# ET6801 register map
Vendor: ETMCU Inc.; File version: v0.0.1
CPU: CM7 r2p1, little endian, MPU, FPU, I-cache, D-cache, ITCM, DTCM, 4 interrupt priority bits
Registers are 32-bit, read-write, reset 0x0 unless marked. A register's access mark holds for its fields unless they carry their own. Offsets are from the block's base; [hi:lo] are bit positions.

## CAN0 (part 1 of 2) — Provide an overview of the purpose and functionality of the peripheral: mttcan_cfg
Base 0x40518000
Same registers: CAN1 0x40520000, CAN2 0x40528000
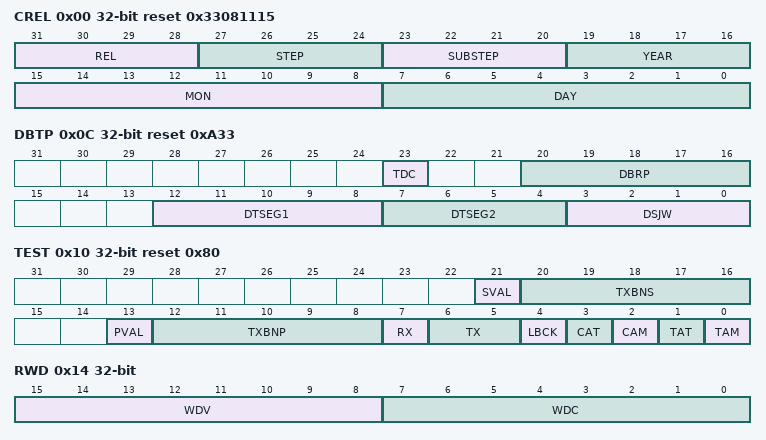
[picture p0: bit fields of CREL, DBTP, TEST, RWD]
0x00 CREL ro reset 0x33081115
  [31:28] REL — Core Release One digit, BCD-coded.
  [27:24] STEP — Step of Core Release One digit, BCD-coded.
  [23:20] SUBSTEP — Sub-step of Core Release One digit, BCD-coded.
  [19:16] YEAR — Time Stamp Year One digit, BCD-coded. This ﬁeld is set by generic parameter on M_TTCAN synthesis.
  [15:8] MON — Time Stamp Month Two digits, BCD-coded. This ﬁeld is set by generic parameter on M_TTCAN synthesis.
  [7:0] DAY — Time Stamp Day Two digits, BCD-coded. This ﬁeld is set by generic parameter on M_TTCAN synthesis.
0x04 ENDN ro reset 0x87654321
  [31:0] ETV — Endianness Test Value The endianness test value is 0x87654321.
0x0C DBTP reset 0xA33
  [23] TDC — Transmitter Delay Compensation 0= Transmitter Delay Compensation disabled 1= Transmitter Delay Compensation enabled
  [20:16] DBRP ro — Data Bit Rate Prescaler 0x00-0x1F The value by which the oscillator frequency is divided for generating the bit time quanta. The bit time is built up from a multiple of this quanta. Valid values for the Bit Rate Prescaler are 0 to 31. When TDC = '1', the range is limited to 0,1. The actual interpretation by the hardware of this value is such that one more than the value programmed here is used.
  [12:8] DTSEG1 ro — Data time segment before sample point 0x00-0x1F Valid values are 0 to 31. The actual interpretation by the hardware of this value is such that one more than the programmed value is used.
  [7:4] DTSEG2 ro — Data time segment after sample point 0x0-0xF Valid values are 0 to 15. The actual interpretation by the hardware of this value is such that one more than the programmed value is used.
  [3:0] DSJW ro — Data (Re)Synchronization Jump Width 0x0-0xF Valid values are 0 to 15. The actual interpretation by the hardware of this value is such that one more than the value programmed here is used.
0x10 TEST ro reset 0x80
  [21] SVAL — Started Valid 0= Value of TXBNS not valid 1= Value of TXBNS valid
  [20:16] TXBNS — Tx Buffer Number Started 0x00-0x1F Tx Buffer number of message whose transmission was started last. Valid when SVAL is set. Valid values are 0 to 31.
  [13] PVAL — Prepared Valid 0= Value of TXBNP not valid 1= Value of TXBNP valid
  [12:8] TXBNP — Tx Buffer Number Prepared 0x00-0x1F Tx Buffer number of message that is ready for transmission. Valid when PVAL is set. Valid values are 0 to 31.
  [7] RX — Receive Pin Monitors the actual value of pin m_ttcan_rx 0= The CAN bus is dominant (m_ttcan_rx = '0') 1= The CAN bus is recessive (m_ttcan_rx = '1')
  [6:5] TX — Control of Transmit Pin 00 Reset value, m_ttcan_tx controlled by the CAN Core, updated at the end of the CAN bit time 01 Sample Point can be monitored at pin m_ttcan_tx 10 Dominant ('0') level at pin m_ttcan_tx 11 Recessive ('1') at pin m_ttcan_tx
  [4] LBCK — Loop Back Mode 0= Reset value, Loop Back Mode is disabled 1= Loop Back Mode is enabled (see Section 3.1.9, Test Modes)
  [3] CAT — Check ASC Transmit Control Monitors level at output pin m_ttcan_asct. 0= Output pin m_ttcan_asct = '0' 1= Output pin m_ttcan_asct = '1'
  [2] CAM — Check ASC Multiplexer Control Monitors level at output pin m_ttcan_ascm. 0= Output pin m_ttcan_ascm = '0' 1= Output pin m_ttcan_ascm = '1'
  [1] TAT — Test ASC Transmit Control Controls output pin m_ttcan_asct in test mode, ORed with the signal from the FSE 0= Level at pin m_ttcan_asct controlled by FSE 1= Level at pin m_ttcan_asct = '1'
  [0] TAM — Test ASC Multiplexer Control Controls output pin m_ttcan_ascm in test mode, ORed with the signal from the FSE 0= Level at pin m_ttcan_ascm controlled by FSE 1= Level at pin m_ttcan_ascm = '1'
0x14 RWD ro
  [15:8] WDV — Watchdog Value Actual Message RAM Watchdog Counter Value.
  [7:0] WDC — Watchdog Conﬁguration Start value of the Message RAM Watchdog Counter. With the reset value of "00" the counter is disabled.
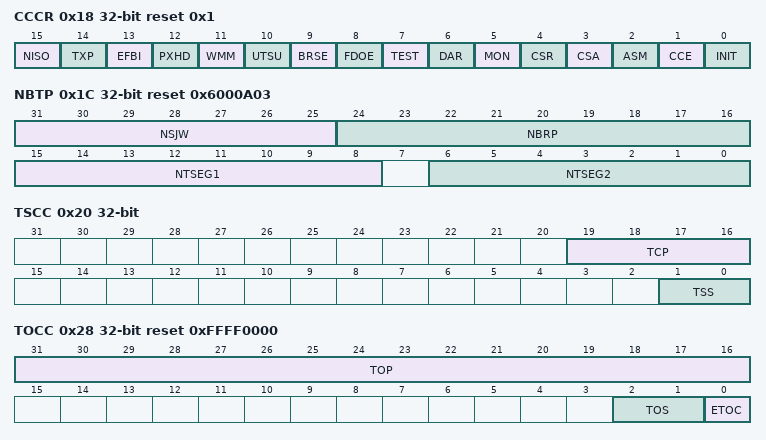
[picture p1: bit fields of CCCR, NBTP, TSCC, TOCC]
0x18 CCCR reset 0x1
  [15] NISO — Non ISO Operation If this bit is set, the M_TTCAN uses the CAN FD frame format as speciﬁed by the Bosch CAN FD Speciﬁcation V1.0. 0= CAN FD frame format according to ISO 11898-1:2015 1= CAN FD frame format according to Bosch CAN FD Speciﬁcation V1.0
  [14] TXP — Transmit Pause If this bit is set, the M_TTCAN pauses for two CAN bit times before starting the next transmission after itself has successfully transmitted a frame (see Section 3.5). 0= Transmit pause disabled 1= Transmit pause enabled
  [13] EFBI — Edge Filtering during Bus Integration 0= Edge ﬁltering disabled 1= Two consecutive dominant tq required to detect an edge for hard synchronization
  [12] PXHD — Protocol Exception Handling Disable 0= Protocol exception handling enabled 1= Protocol exception handling disabled
  [11] WMM — Wide Message Marker Enables the use of 16-bit Wide Message Markers. When 16-bit Wide Message Markers are used (WMM = '1'), 16-bit internal timestamping is disabled for the Tx Event FIFO. 0= 8-bit Message Marker used 1= 16-bit Message Marker used, replacing 16-bit timestamps in Tx Event FIFO
  [10] UTSU — Use Timestamping Unit When UTSU is set, 16-bit Wide Message Markers are also enabled regardless of the value of WMM. 0= Internal time stamping 1= External time stamping by TSU
  [9] BRSE — Bit Rate Switch Enable 0= Bit rate switching for transmissions disabled 1= Bit rate switching for transmissions enabled
  [8] FDOE — FD Operation Enable 0= FD operation disabled 1= FD operation enabled
  [7] TEST — Test Mode Enable 0= Normal operation, register TEST holds reset values 1= Test Mode, write access to register TEST enabled
  [6] DAR — Disable Automatic Retransmission 0= Automatic retransmission of messages not transmitted successfully enabled 1= Automatic retransmission disabled
  [5] MON — Bus Monitoring Mode Bit MON can only be set by the Host when both CCE and INIT are set to '1'. The bit can be reset by the Host at any time. 0= Bus Monitoring Mode is disabled 1= Bus Monitoring Mode is enabled
  [4] CSR — Clock Stop Request 0= No clock stop is requested 1= Clock stop requested. When clock stop is requested, ﬁrst INIT and then CSA will be set after all pending transfer requests have been completed and the CAN bus reached idle.
  [3] CSA — Clock Stop Acknowledge 0= No clock stop acknowledged 1= M_TTCAN may be set in power down by stopping m_ttcan_hclk and m_ttcan_cclk
  [2] ASM — Restricted Operation Mode Bit ASM can only be set by the Host when both CCE and INIT are set to '1'. The bit can be reset by the Host at any time. For a description of the Restricted Operation Mode see Section 3.1.5. 0= Normal CAN operation 1= Restricted Operation Mode active
  [1] CCE — Conﬁguration Change Enable 0= The CPU has no write access to the protected conﬁguration registers 1= The CPU has write access to the protected conﬁguration registers (while CCCR.INIT = '1')
  [0] INIT — Initialization 0= Normal Operation 1= Initialization is started
0x1C NBTP ro reset 0x6000A03
  [31:25] NSJW — Nominal (Re)Synchronization Jump Width 0x00-0x7F Valid values are 0 to 127. The actual interpretation by the hardware of this value is such that one more than the value programmed here is used.
  [24:16] NBRP — Nominal Bit Rate Prescaler 0x000-0x1FFThe value by which the oscillator frequency is divided for generating the bit time quanta. The bit time is built up from a multiple of this quanta. Valid values for the Bit Rate Prescaler are 0 to 511. The actual interpretation by the hardware of this value is such that one more than the value programmed here is used.
  [15:8] NTSEG1 — Nominal Time segment before sample point 0x01-0xFF Valid values are 1 to 255. The actual interpretation by the hardware of this value is such that one more than the programmed value is used.
  [6:0] NTSEG2 — Nominal Time segment after sample point 0x01-0x7F Valid values are 1 to 127. The actual interpretation by the hardware of this value is such that one more than the programmed value is used.
0x20 TSCC ro
  [19:16] TCP — Timestamp Counter Prescaler 0x0-0xF Conﬁgures the timestamp and timeout counters time unit in multiples of CAN bit times [1...16]. The actual interpretation by the hardware of this value is such that one more than the value programmed here is used.
  [1:0] TSS — Timestamp Select 00= Timestamp counter value always 0x0000 01= Timestamp counter value incremented according to TCP 10= External timestamp counter value used 11= Same as "00"
0x24 TSCV ro
  [15:0] TSC — Timestamp Counter The internal/external Timestamp Counter value is captured on start of frame (both Rx and Tx). When TSCC.TSS = "01", the Timestamp Counter is incremented in multiples of CAN bit times [1...16] depending on the conﬁguration of TSCC.TCP. A wrap around sets interrupt ﬂag IR.TSW. Write access resets the counter to zero. When TSCC.TSS = "10", TSC reﬂects the external Timestamp Counter value. A write access has no impact.
0x28 TOCC ro reset 0xFFFF0000
  [31:16] TOP — Timeout Period Start value of the Timeout Counter (down-counter). Conﬁgures the Timeout Period.
  [2:1] TOS — Timeout Select When operating in Continuous mode, a write to TOCV presets the counter to the value conﬁgured by TOCC.TOP and continues down-counting. When the Timeout Counter is controlled by one of the FIFOs, an empty FIFO presets the counter to the value conﬁgured by TOCC.TOP. Down-counting is started when the ﬁrst FIFO element is stored. 00= Continuous operation 01= Timeout controlled by Tx Event FIFO 10= Timeout controlled by Rx FIFO 0 11= Timeout controlled by Rx FIFO 1
  [0] ETOC — Enable Timeout Counter 0= Timeout Counter disabled 1= Timeout Counter enabled
0x2C TOCV ro reset 0xFFFF
  [15:0] TOC — Timeout Counter The Timeout Counter is decremented in multiples of CAN bit times [1...16] depending on the conﬁguration of TSCC.TCP. When decremented to zero, interrupt ﬂag IR.TOO is set and the Timeout Counter is stopped. Start and reset/restart conditions are conﬁgured via TOCC.TOS.
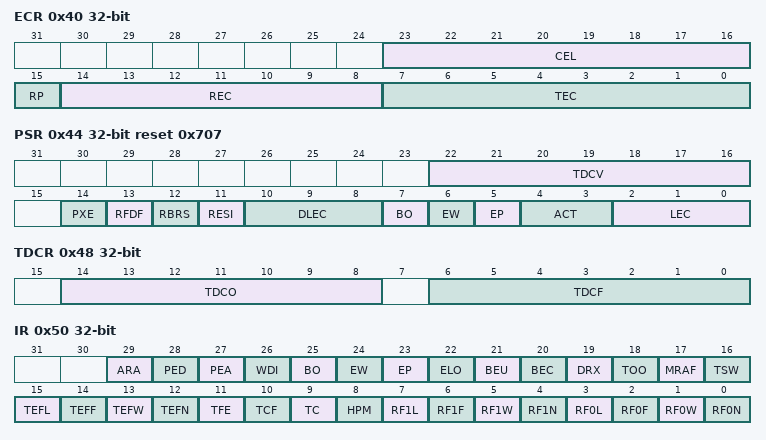
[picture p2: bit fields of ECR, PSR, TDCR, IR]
0x40 ECR ro
  [23:16] CEL — CAN Error Logging The counter is incremented each time when a CAN protocol error causes the 8-bit Transmit Error Counter TEC or the 7-bit Receive Error Counter REC to be incremented. The counter is also incremented when the Bus_Off limit is reached. It is not incremented when only RP is set without changing REC. The increment of CEL follows after the increment of REC or TEC. The counter is reset by read access to CEL. The counter stops at 0xFF; the next increment of TEC or REC sets interrupt ﬂag IR.ELO.
  [15] RP — Receive Error Passive 0= The Receive Error Counter is below the error passive level of 128 1= The Receive Error Counter has reached the error passive level of 128
  [14:8] REC — Receive Error Counter Actual state of the Receive Error Counter, values between 0 and 127
  [7:0] TEC — Transmit Error Counter Actual state of the Transmit Error Counter, values between 0 and 255
0x44 PSR ro reset 0x707
  [22:16] TDCV — Transmitter Delay Compensation Value 0x00-0x7F Position of the secondary sample point, deﬁned by the sum of the measured delay from m_ttcan_tx to m_ttcan_rx and TDCR.TDCO. The SSP position is, in the data phase, the number of mtq between the start of the transmitted bit and the secondary sample point Valid values are 0 to 127 mtq.
  [14] PXE — Protocol Exception Event 0= No protocol exception event occurred since last read access 1= Protocol exception event occurred
  [13] RFDF — Received a CAN FD Message This bit is set independent of acceptance ﬁltering. 0= Since this bit was reset by the CPU, no CAN FD message has been received 1= Message in CAN FD format with FDF ﬂag set has been received
  [12] RBRS — BRS ﬂag of last received CAN FD Message This bit is set together with RFDF, independent of acceptance ﬁltering. 0= Last received CAN FD message did not have its BRS ﬂag set 1= Last received CAN FD message had its BRS ﬂag set
  [11] RESI — ESI ﬂag of last received CAN FD Message This bit is set together with RFDF, independent of acceptance ﬁltering. 0= Last received CAN FD message did not have its ESI ﬂag set 1= Last received CAN FD message had its ESI ﬂag set
  [10:8] DLEC — Data Phase Last Error Code Type of last error that occurred in the data phase of a CAN FD format frame with its BRS ﬂag set. Coding is the same as for LEC. This ﬁeld will be cleared to zero when a CAN FD format frame with its BRS ﬂag set has been transferred (reception or transmission) without error.
  [7] BO — Bus_Off Status 0= The M_TTCAN is not Bus_Off 1= The M_TTCAN is in Bus_Off state
  [6] EW — Warning Status 0= Both error counters are below the Error_Warning limit of 96 1= At least one of error counter has reached the Error_Warning limit of 96
  [5] EP — Error Passive 0= The M_TTCAN is in the Error_Active state. It normally takes part in bus communication and sends an active error ﬂag when an error has been detected 1= The M_TTCAN is in the Error_Passive state
  [4:3] ACT — Activity Monitors the module's CAN communication state. 00= Synchronizing - node is synchronizing on CAN communication 01= Idle - node is neither receiver nor transmitter 10= Receiver - node is operating as receiver 11= Transmitter - node is operating as transmitter
  [2:0] LEC — Last Error Code The LEC indicates the type of the last error to occur on the CAN bus. This ﬁeld will be cleared to '0' when a message has been transferred (reception or transmission) without error.
0x48 TDCR ro
  [14:8] TDCO — Transmitter Delay Compensation SSP Offset 0x00-0x7F Offset value deﬁning the distance between the measured delay from m_ttcan_tx to m_ttcan_rx and the secondary sample point. Valid values are 0 to 127 mtq.
  [6:0] TDCF — Transmitter Delay Compensation Filter Window Length 0x00-0x7F Deﬁnes the minimum value for the SSP position, dominant edges on m_ttcan_rx that would result in an earlier SSP position are ignored for transmitter delay measurement. The feature is enabled when TDCF is conﬁgured to a value greater than TDCO. Valid values are 0 to 127 mtq.
0x50 IR
  [29] ARA — Access to Reserved Address 0= No access to reserved address occurred 1= Access to reserved address occurred
  [28] PED — Protocol Error in Data Phase (Data Bit Time is used) 0= No protocol error in data phase 1= Protocol error in data phase detected (PSR.DLEC ≠ 0,7)
  [27] PEA — Protocol Error in Arbitration Phase (Nominal Bit Time is used) 0= No protocol error in arbitration phase 1= Protocol error in arbitration phase detected (PSR.LEC ≠ 0,7)
  [26] WDI — Watchdog Interrupt 0= No Message RAM Watchdog event occurred 1= Message RAM Watchdog event due to missing READY
  [25] BO — Bus_Off Status 0= Bus_Off status unchanged 1= Bus_Off status changed
  [24] EW — Warning Status 0= Error_Warning status unchanged 1= Error_Warning status changed
  [23] EP — Error Passive 0= Error_Passive status unchanged 1= Error_Passive status changed
  [22] ELO — Error Logging Overﬂow 0= CAN Error Logging Counter did not overﬂow 1= Overﬂow of CAN Error Logging Counter occurred
  [21] BEU — Bit Error Uncorrected Message RAM bit error detected, uncorrected. Controlled by input signal m_ttcan_aeim_berr[1] generated by an optional external parity / ECC logic attached to the Message RAM. An uncorrected Message RAM bit error sets CCCR.INIT to '1'. This is done to avoid transmission of corrupted data. 0= No bit error detected when reading from Message RAM 1= Bit error detected, uncorrected (e.g. parity logic)
  [20] BEC — Bit Error Corrected Message RAM bit error detected and corrected. Controlled by input signal m_ttcan_aeim_berr[0] generated by an optional external parity / ECC logic attached to the Message RAM. 0= No bit error detected when reading from Message RAM 1= Bit error detected and corrected (e.g. ECC)
  [19] DRX — Message stored to Dedicated Rx Buffer The ﬂag is set whenever a received message has been stored into a dedicated Rx Buffer. 0= No Rx Buffer updated 1= At least one received message stored into a Rx Buffer
  [18] TOO — Timeout Occurred 0= No timeout 1= Timeout reached
  [17] MRAF — Message RAM Access Failure The ﬂag is set, when the Rx Handler • has not completed acceptance ﬁltering or storage of an accepted message until the arbitration ﬁeld of the following message has been received. In this case acceptance ﬁltering or message storage is aborted and the Rx Handler starts processing of the following message. • was not able to write a message to the Message RAM. In this case message storage is aborted. In both cases the FIFO put index is not updated resp. the New Data ﬂag for a dedicated Rx Buffer is not set, a partly stored message is overwritten when the next message is stored to this location. The ﬂag is also set when the Tx Handler was not able to read a message from the Message RAM in time. In this case message transmission is aborted. In case of a Tx Handler access failure the M_TTCAN is switched into Restricted Operation Mode (see Section 3.1.5). To leave Restricted Operation Mode, the Host CPU has to reset CCCR.ASM. 0= No Message RAM access failure occurred 1= Message RAM access failure occurred
  [16] TSW — Timestamp Wraparound 0= No timestamp counter wrap-around 1= Timestamp counter wrapped around
  [15] TEFL — Tx Event FIFO Element Lost 0= No Tx Event FIFO element lost 1= Tx Event FIFO element lost, also set after write attempt to Tx Event FIFO of size zero
  [14] TEFF — Tx Event FIFO Full 0= Tx Event FIFO not full 1= Tx Event FIFO full
  [13] TEFW — Tx Event FIFO Watermark Reached 0= Tx Event FIFO ﬁll level below watermark 1= Tx Event FIFO ﬁll level reached watermark
  [12] TEFN — Tx Event FIFO New Entry 0= Tx Event FIFO unchanged 1= Tx Handler wrote Tx Event FIFO element
  [11] TFE — Tx FIFO Empty 0= Tx FIFO non-empty 1= Tx FIFO empty
  [10] TCF — Transmission Cancellation Finished 0= No transmission cancellation ﬁnished 1= Transmission cancellation ﬁnished
  [9] TC — Transmission Completed 0= No transmission completed 1= Transmission completed
  [8] HPM — High Priority Message 0= No high priority message received 1= High priority message received
  [7] RF1L — Rx FIFO 1 Message Lost 0= No Rx FIFO 1 message lost 1= Rx FIFO 1 message lost, also set after write attempt to Rx FIFO 1 of size zero
  [6] RF1F — Rx FIFO 1 Full 0= Rx FIFO 1 not full 1= Rx FIFO 1 full
  [5] RF1W — Rx FIFO 1 Watermark Reached 0= Rx FIFO 1 ﬁll level below watermark 1= Rx FIFO 1 ﬁll level reached watermark
  [4] RF1N — Rx FIFO 1 New Message 0= No new message written to Rx FIFO 1 1= New message written to Rx FIFO 1
  [3] RF0L — Rx FIFO 0 Message Lost 0= No Rx FIFO 0 message lost 1= Rx FIFO 0 message lost, also set after write attempt to Rx FIFO 0 of size zero
  [2] RF0F — Rx FIFO 0 Full 0= Rx FIFO 0 not full 1= Rx FIFO 0 full
  [1] RF0W — Rx FIFO 0 Watermark Reached 0= Rx FIFO 0 ﬁll level below watermark 1= Rx FIFO 0 ﬁll level reached watermark
  [0] RF0N — Rx FIFO 0 New Message 0= No new message written to Rx FIFO 0 1= New message written to Rx FIFO 0
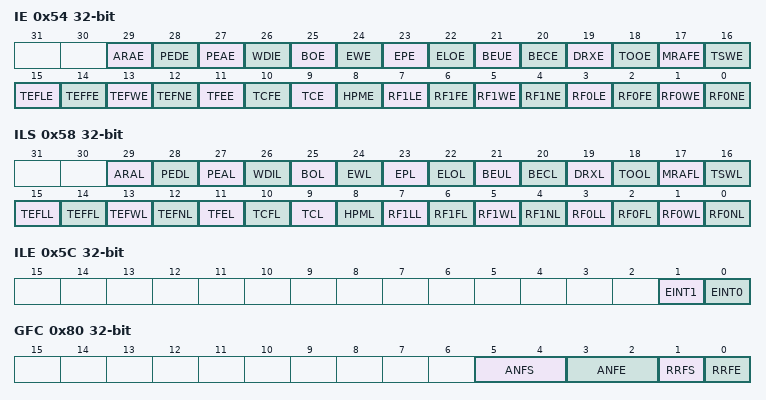
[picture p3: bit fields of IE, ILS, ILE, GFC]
0x54 IE
  [29] ARAE — Access to Reserved Address Enable
  [28] PEDE — Protocol Error in Data Phase Enable
  [27] PEAE — Protocol Error in Arbitration Phase Enable
  [26] WDIE — Watchdog Interrupt Enable
  [25] BOE — Bus_Off Status Interrupt Enable
  [24] EWE — Warning Status Interrupt Enable
  [23] EPE — Error Passive Interrupt Enable
  [22] ELOE — Error Logging Overﬂow Interrupt Enable
  [21] BEUE — Bit Error Uncorrected Interrupt Enable
  [20] BECE — Bit Error Corrected Interrupt Enable
  [19] DRXE — Message stored to Dedicated Rx Buffer Interrupt Enable
  [18] TOOE — Timeout Occurred Interrupt Enable
  [17] MRAFE — Message RAM Access Failure Interrupt Enable
  [16] TSWE — Timestamp Wraparound Interrupt Enable
  [15] TEFLE — Tx Event FIFO Event Lost Interrupt Enable
  [14] TEFFE — Tx Event FIFO Full Interrupt Enable
  [13] TEFWE — Tx Event FIFO Watermark Reached Interrupt Enable
  [12] TEFNE — Tx Event FIDO New Entry Interrupt Enable
  [11] TFEE — Tx FIFO Empty Interrupt Enable
  [10] TCFE — Transmission Cancellation Finished Interrupt Enable
  [9] TCE — Transmission Completed Interrupt Enable
  [8] HPME — High Priority Message Interrupt Enable
  [7] RF1LE — Rx FIFO 1 Message Lost Interrupt Enable
  [6] RF1FE — Rx FIFO 1 Full Interrupt Enable
  [5] RF1WE — Rx FIFO 1 Watermark Reached Interrupt Enable
  [4] RF1NE — Rx FIFO 1 New Message Interrupt Enable
  [3] RF0LE — Rx FIFO 0 Message Lost Interrupt Enable
  [2] RF0FE — Rx FIFO 0 Full Interrupt Enable
  [1] RF0WE — Rx FIFO 0 Watermark Reached Interrupt Enable
  [0] RF0NE — Rx FIFO 0 New Message Interrupt Enable
0x58 ILS
  [29] ARAL — Access to Reserved Address Line
  [28] PEDL — Protocol Error in Data Phase Line
  [27] PEAL — Protocol Error in Arbitration Phase Line
  [26] WDIL — Watchdog Interrupt Line
  [25] BOL — Bus_Off Status Interrupt Line
  [24] EWL — Warning Status Interrupt Line
  [23] EPL — Error Passive Interrupt Line
  [22] ELOL — Error Logging Overﬂow Interrupt Line
  [21] BEUL — Bit Error Uncorrected Interrupt Line
  [20] BECL — Bit Error Corrected Interrupt Line
  [19] DRXL — Message stored to Dedicated Rx Buffer Interrupt Line
  [18] TOOL — Timeout Occurred Interrupt Line
  [17] MRAFL — Message RAM Access Failure Interrupt Line
  [16] TSWL — Timestamp Wraparound Interrupt Line
  [15] TEFLL — Tx Event FIFO Event Lost Interrupt Line
  [14] TEFFL — Tx Event FIFO Full Interrupt Line
  [13] TEFWL — Tx Event FIFO Watermark Reached Interrupt Line
  [12] TEFNL — Tx Event FIFO New Entry Interrupt Line
  [11] TFEL — Tx FIFO Empty Interrupt Line
  [10] TCFL — Transmission Cancellation Finished Interrupt Line
  [9] TCL — Transmission Completed Interrupt Line
  [8] HPML — High Priority Message Interrupt Line
  [7] RF1LL — Rx FIFO 1 Message Lost Interrupt Line
  [6] RF1FL — Rx FIFO 1 Full Interrupt Line
  [5] RF1WL — Rx FIFO 1 Watermark Reached Interrupt Line
  [4] RF1NL — Rx FIFO 1 New Message Interrupt Line
  [3] RF0LL — Rx FIFO 0 Message Lost Interrupt Line
  [2] RF0FL — Rx FIFO 0 Full Interrupt Line
  [1] RF0WL — Rx FIFO 0 Watermark Reached Interrupt Line
  [0] RF0NL — Rx FIFO 0 New Message Interrupt Line
0x5C ILE
  [1] EINT1 — Enable Interrupt Line 1 0= Interrupt line m_ttcan_int1 disabled 1= Interrupt line m_ttcan_int1 enabled
  [0] EINT0 — Enable Interrupt Line 0 0= Interrupt line m_ttcan_int0 disabled 1= Interrupt line m_ttcan_int0 enabled
0x80 GFC ro
  [5:4] ANFS — Accept Non-matching Frames Standard Deﬁnes how received messages with 11-bit IDs that do not match any element of the ﬁlter list are treated. 00= Accept in Rx FIFO 0 01= Accept in Rx FIFO 1 10= Reject 11= Reject
  [3:2] ANFE — Accept Non-matching Frames Extended Deﬁnes how received messages with 29-bit IDs that do not match any element of the ﬁlter list are treated. 00= Accept in Rx FIFO 0 01= Accept in Rx FIFO 1 10= Reject 11= Reject
  [1] RRFS — Reject Remote Frames Standard 0= Filter remote frames with 11-bit standard IDs 1= Reject all remote frames with 11-bit standard IDs
  [0] RRFE — Reject Remote Frames Extended 0= Filter remote frames with 29-bit extended IDs 1= Reject all remote frames with 29-bit extended IDs
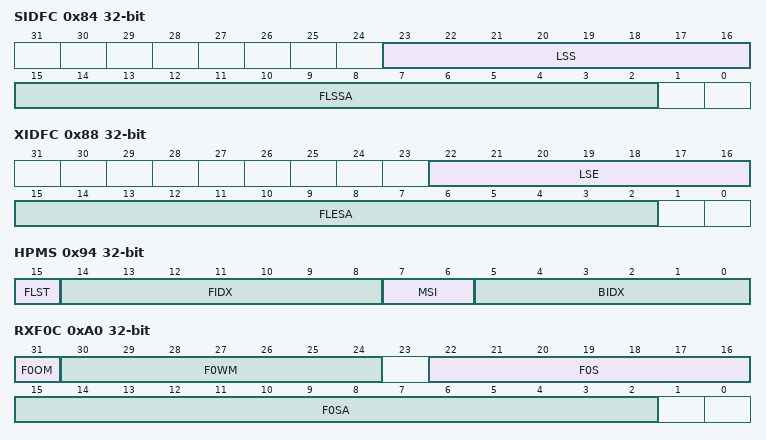
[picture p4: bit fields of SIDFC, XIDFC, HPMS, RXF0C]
0x84 SIDFC ro
  [23:16] LSS — List Size Standard 0= No standard Message ID ﬁlter 1-128= Number of standard Message ID ﬁlter elements >128= Values greater than 128 are interpreted as 128
  [15:2] FLSSA — Filter List Standard Start Address Start address of standard Message ID ﬁlter list (32-bit word address, see Figure 2).
0x88 XIDFC ro
  [22:16] LSE — List Size Extended 0= No extended Message ID ﬁlter 1-64= Number of extended Message ID ﬁlter elements >64= Values greater than 64 are interpreted as 64
  [15:2] FLESA — Filter List Extended Start Address Start address of extended Message ID ﬁlter list (32-bit word address, see Figure 2).
0x90 XIDAM ro reset 0x1FFFFFFF
  [28:0] EIDM — Extended ID Mask For acceptance ﬁltering of extended frames the Extended ID AND Mask is ANDed with the Message ID of a received frame. Intended for masking of 29-bit IDs in SAE J1939. With the reset value of all bits set to one the mask is not active.
0x94 HPMS ro
  [15] FLST — Filter List Indicates the ﬁlter list of the matching ﬁlter element. 0= Standard Filter List 1= Extended Filter List
  [14:8] FIDX — Filter Index Index of matching ﬁlter element. Range is 0 to SIDFC.LSS - 1 resp. XIDFC.LSE - 1.
  [7:6] MSI — Message Storage Indicator 00= No FIFO selected 01= FIFO message lost 10= Message stored in FIFO 0 11= Message stored in FIFO 1
  [5:0] BIDX — Buffer Index Index of Rx FIFO element to which the message was stored. Only valid when MSI[1] = '1'.
0x98 NDAT1
  [31:0] ND — New Data The register holds the New Data ﬂags of Rx Buffers 0 to 31. The ﬂags are set when the respective Rx Buffer has been updated from a received frame. The ﬂags remain set until the Host clears them. A flag is cleared by writing a '1' to the corresponding bit position. Writing a '0' has no effect. A hard reset will clear the register. 0= Rx Buffer not updated 1= Rx Buffer updated from new message
0x9C NDAT2
  [31:0] ND — New Data The register holds the New Data ﬂags of Rx Buffers 32 to 63. The ﬂags are set when the respective Rx Buffer has been updated from a received frame. The ﬂags remain set until the Host clears them. A flag is cleared by writing a '1' to the corresponding bit position. Writing a '0' has no effect. A hard reset will clear the register. 0= Rx Buffer not updated 1= Rx Buffer updated from new message
0xA0 RXF0C ro
  [31] F0OM — FIFO 0 Operation Mode FIFO 0 can be operated in blocking or in overwrite mode (see Section 3.4.2). 0= FIFO 0 blocking mode 1= FIFO 0 overwrite mode
  [30:24] F0WM — Rx FIFO 0 Watermark 0= Watermark interrupt disabled 1-64= Level for Rx FIFO 0 watermark interrupt (IR.RF0W) >64= Watermark interrupt disabled
  [22:16] F0S — Rx FIFO 0 Size 0= No Rx FIFO 0 1-64= Number of Rx FIFO 0 elements >64= Values greater than 64 are interpreted as 64 The Rx FIFO 0 elements are indexed from 0 to F0S-1
  [15:2] F0SA — Rx FIFO 0 Start Address Start address of Rx FIFO 0 in Message RAM (32-bit word address, see Figure 2).
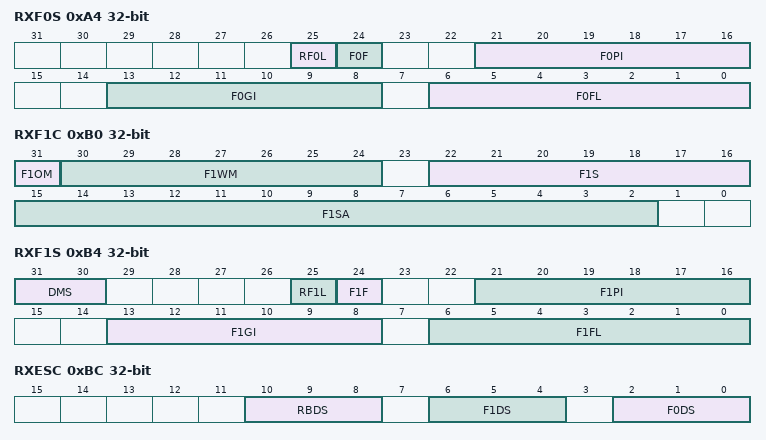
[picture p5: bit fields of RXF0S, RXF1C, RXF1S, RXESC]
0xA4 RXF0S ro
  [25] RF0L — Rx FIFO 0 Message Lost This bit is a copy of interrupt ﬂag IR.RF0L. When IR.RF0L is reset, this bit is also reset. 0= No Rx FIFO 0 message lost 1= Rx FIFO 0 message lost, also set after write attempt to Rx FIFO 0 of size zero
  [24] F0F — Rx FIFO 0 Full 0= Rx FIFO 0 not full 1= Rx FIFO 0 full
  [21:16] F0PI — Rx FIFO 0 Put Index Rx FIFO 0 write index pointer, range 0 to 63.
  [13:8] F0GI — Rx FIFO 0 Get Index Rx FIFO 0 read index pointer, range 0 to 63.
  [6:0] F0FL — Rx FIFO 0 Fill Level Number of elements stored in Rx FIFO 0, range 0 to 64.
0xA8 RXF0A
  [5:0] F0AI — Rx FIFO 0 Acknowledge Index After the Host has read a message or a sequence of messages from Rx FIFO 0 it has to write the buffer index of the last element read from Rx FIFO 0 to F0AI. This will set the Rx FIFO 0 Get Index RXF0S.F0GI to F0AI + 1 and update the FIFO 0 Fill Level RXF0S.F0FL.
0xAC RXBC ro
  [15:2] RBSA — Rx Buffer Start Address Conﬁgures the start address of the Rx Buffers section in the Message RAM (32-bit word address). Also used to reference debug messages A,B,C.
0xB0 RXF1C ro
  [31] F1OM — FIFO 1 Operation Mode FIFO 1 can be operated in blocking or in overwrite mode (see Section 3.4.2). 0= FIFO 1 blocking mode 1= FIFO 1 overwrite mode
  [30:24] F1WM — Rx FIFO 1 Watermark 0= Watermark interrupt disabled 1-64= Level for Rx FIFO 1 watermark interrupt (IR.RF1W) >64= Watermark interrupt disabled
  [22:16] F1S — Rx FIFO 1 Size 0= No Rx FIFO 1 1-64= Number of Rx FIFO 1 elements >64= Values greater than 64 are interpreted as 64 The Rx FIFO 1 elements are indexed from 0 to F1S - 1
  [15:2] F1SA — Rx FIFO 1 Start Address Start address of Rx FIFO 1 in Message RAM (32-bit word address, see Figure 2).
0xB4 RXF1S ro
  [31:30] DMS — Debug Message Status 00= Idle state, wait for reception of debug messages, DMA request is cleared 01= Debug message A received 10= Debug messages A, B received 11= Debug messages A, B, C received, DMA request is set
  [25] RF1L — Rx FIFO 1 Message Lost This bit is a copy of interrupt ﬂag IR.RF1L. When IR.RF1L is reset, this bit is also reset. 0= No Rx FIFO 1 message lost 1= Rx FIFO 1 message lost, also set after write attempt to Rx FIFO 1 of size zero
  [24] F1F — Rx FIFO 1 Full 0= Rx FIFO 1 not full 1= Rx FIFO 1 full
  [21:16] F1PI — Rx FIFO 1 Put Index Rx FIFO 1 write index pointer, range 0 to 63.
  [13:8] F1GI — Rx FIFO 1 Get Index Rx FIFO 1 read index pointer, range 0 to 63.
  [6:0] F1FL — Rx FIFO 1 Fill Level Number of elements stored in Rx FIFO 1, range 0 to 64.
0xB8 RXF1A
  [5:0] F1AI — Rx FIFO 1 Acknowledge Index After the Host has read a message or a sequence of messages from Rx FIFO 1 it has to write the buffer index of the last element read from Rx FIFO 1 to F1AI. This will set the Rx FIFO 1 Get Index RXF1S.F1GI to F1AI + 1 and update the FIFO 1 Fill Level RXF1S.F1FL.
0xBC RXESC ro
  [10:8] RBDS — Rx Buffer Data Field Size 000= 8 byte data ﬁeld 001= 12 byte data ﬁeld 010= 16 byte data ﬁeld 011= 20 byte data ﬁeld 100= 24 byte data ﬁeld 101= 32 byte data ﬁeld 110= 48 byte data ﬁeld 111= 64 byte data ﬁeld
  [6:4] F1DS — Rx FIFO 1 Data Field Size 000= 8 byte data ﬁeld 001= 12 byte data ﬁeld 010= 16 byte data ﬁeld 011= 20 byte data ﬁeld 100= 24 byte data ﬁeld 101= 32 byte data ﬁeld 110= 48 byte data ﬁeld 111= 64 byte data ﬁeld
  [2:0] F0DS — Rx FIFO 0 Data Field Size 000= 8 byte data ﬁeld 001= 12 byte data ﬁeld 010= 16 byte data ﬁeld 011= 20 byte data ﬁeld 100= 24 byte data ﬁeld 101= 32 byte data ﬁeld 110= 48 byte data ﬁeld 111= 64 byte data ﬁeld
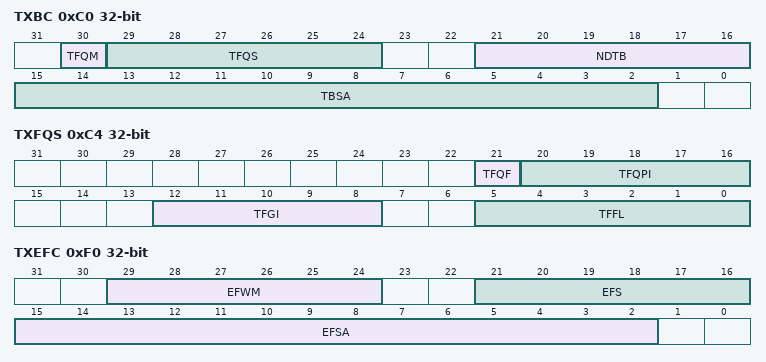
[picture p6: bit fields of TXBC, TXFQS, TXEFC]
0xC0 TXBC ro
  [30] TFQM — Tx FIFO/Queue Mode 0= Tx FIFO operation 1= Tx Queue operation
  [29:24] TFQS — Transmit FIFO/Queue Size 0= No Tx FIFO/Queue 1-32= Number of Tx Buffers used for Tx FIFO/Queue >32= Values greater than 32 are interpreted as 32
  [21:16] NDTB — Number of Dedicated Transmit Buffers 0= No Dedicated Tx Buffers 1-32= Number of Dedicated Tx Buffers >32= Values greater than 32 are interpreted as 32
  [15:2] TBSA — Tx Buffers Start Address Start address of Tx Buffers section in Message RAM (32-bit word address, see Figure 2).
0xC4 TXFQS ro
  [21] TFQF — Tx FIFO/Queue Full 0= Tx FIFO/Queue not full 1= Tx FIFO/Queue full
  [20:16] TFQPI — Tx FIFO/Queue Put Index Tx FIFO/Queue write index pointer, range 0 to 31.
  [12:8] TFGI — Tx FIFO Get Index Tx FIFO read index pointer, range 0 to 31. Read as zero when Tx Queue operation is conﬁgured (TXBC.TFQM = '1').
  [5:0] TFFL — Tx FIFO Free Level Number of consecutive free Tx FIFO elements starting from TFGI, range 0 to 32. Read as zero when Tx Queue operation is conﬁgured (TXBC.TFQM = '1')
0xC8 TXESC ro
  [2:0] TBDS — Tx Buffer Data Field Size 000= 8 byte data ﬁeld 001= 12 byte data ﬁeld 010= 16 byte data ﬁeld 011= 20 byte data ﬁeld 100= 24 byte data ﬁeld 101= 32 byte data ﬁeld 110= 48 byte data ﬁeld 111= 64 byte data ﬁeld
0xCC TXBRP ro
  [31:0] TRP — Transmission Request Pending Each Tx Buffer has its own Transmission Request Pending bit. The bits are set via register TXBAR. The bits are reset after a requested transmission has completed or has been cancelled via register TXBCR. TXBRP bits are set only for those Tx Buffers conﬁgured via TXBC. After a TXBRP bit has been set, a Tx scan (see Section 3.5, Tx Handling) is started to check for the pending Tx request with the highest priority (Tx Buffer with lowest Message ID). A cancellation request resets the corresponding transmission request pending bit of register TXBRP. In case a transmission has already been started when a cancellation is requested, this is done at the end of the transmission, regardless whether the transmission was successful or not. The cancellation request bits are reset directly after the corresponding TXBRP bit has been reset. After a cancellation has been requested, a ﬁnished cancellation is signalled via TXBCF • after successful transmission together with the corresponding TXBTO bit • when the transmission has not yet been started at the point of cancellation • when the transmission has been aborted due to lost arbitration • when an error occurred during frame transmission In DAR mode all transmissions are automatically cancelled if they are not successful. The corresponding TXBCF bit is set for all unsuccessful transmissions. 0= No transmission request pending 1= Transmission request pending
0xD0 TXBAR
  [31:0] AR — Add Request Each Tx Buffer has its own Add Request bit. Writing a '1' will set the corresponding Add Request bit; writing a '0' has no impact. This enables the Host to set transmission requests for multiple Tx Buffers with one write to TXBAR. TXBAR bits are set only for those Tx Buffers conﬁgured via TXBC. When no Tx scan is running, the bits are reset immediately, else the bits remain set until the Tx scan process has completed. 0= No transmission request added 1= Transmission requested added
0xD4 TXBCR
  [31:0] CR — Cancellation Request Each Tx Buffer has its own Cancellation Request bit. Writing a '1' will set the corresponding Cancellation Request bit; writing a '0' has no impact. This enables the Host to set cancellation requests for multiple Tx Buffers with one write to TXBCR. TXBCR bits are set only for those Tx Buffers conﬁgured via TXBC. The bits remain set until the corresponding bit of TXBRP is reset. 0= No cancellation pending 1= Cancellation pending
0xD8 TXBTO ro
  [31:0] TO — Transmission Occurred Each Tx Buffer has its own Transmission Occurred bit. The bits are set when the corresponding TXBRP bit is cleared after a successful transmission. The bits are reset when a new transmission is requested by writing a '1' to the corresponding bit of register TXBAR. 0= No transmission occurred 1= Transmission occurred
0xDC TXBCF ro
  [31:0] CF — Cancellation Finished Each Tx Buffer has its own Cancellation Finished bit. The bits are set when the corresponding TXBRP bit is cleared after a cancellation was requested via TXBCR. In case the corresponding TXBRP bit was not set at the point of cancellation, CF is set immediately. The bits are reset when a new transmission is requested by writing a '1' to the corresponding bit of register TXBAR. 0= No transmit buffer cancellation 1= Transmit buffer cancellation ﬁnished
0xE0 TXBTIE
  [31:0] TIE — Transmission Interrupt Enable Each Tx Buffer has its own Transmission Interrupt Enable bit. 0= Transmission interrupt disabled 1= Transmission interrupt enable
0xE4 TXBCIE
  [31:0] CFIE — Cancellation Finished Interrupt Enable Each Tx Buffer has its own Cancellation Finished Interrupt Enable bit. 0= Cancellation ﬁnished interrupt disabled 1= Cancellation ﬁnished interrupt enabled
0xF0 TXEFC ro
  [29:24] EFWM — Event FIFO Watermark 0= Watermark interrupt disabled 1-32= Level for Tx Event FIFO watermark interrupt (IR.TEFW) >32= Watermark interrupt disabled
  [21:16] EFS — Event FIFO Size 0= Tx Event FIFO disabled 1-32= Number of Tx Event FIFO elements >32= Values greater than 32 are interpreted as 32 The Tx Event FIFO elements are indexed from 0 to EFS-1
  [15:2] EFSA — Event FIFO Start Address Start address of Tx Event FIFO in Message RAM (32-bit word address, see Figure 2).
